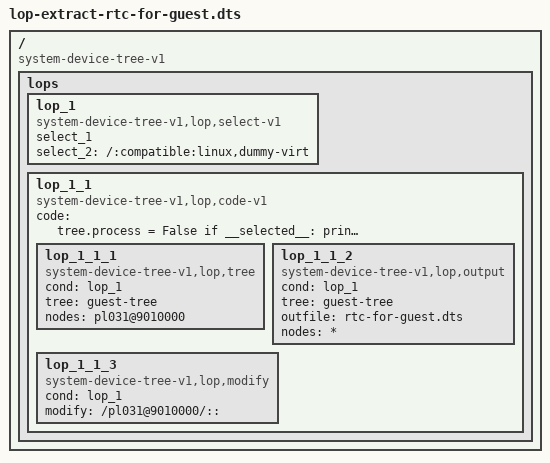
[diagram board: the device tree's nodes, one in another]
/dts-v1/;

/ {
	compatible = "system-device-tree-v1";
	lops {
		// Select the QEMU virt device tree (compatible = "linux,dummy-virt")
		lop_1: lop_1 {
			compatible = "system-device-tree-v1,lop,select-v1";
			// clear any old selections
			select_1;
			select_2 = "/:compatible:linux,dummy-virt";
		};

		lop_1_1: lop_1_1 {
			compatible = "system-device-tree-v1,lop,code-v1";
			code = "
				tree.process = False
				if __selected__:
					print('Compatible dts (qemu virt) found: %s' % node)
					tree.process = True

				if __selected__:
					return True
				else:
					return False
				";

			// Build a virtual tree containing only the RTC node
			lop_1_1_1 {
				compatible = "system-device-tree-v1,lop,tree";
				cond = <&lop_1>;
				tree = "guest-tree";
				nodes = "pl031@9010000";
			};

			// Output the guest tree to rtc-for-guest.dts
			lop_1_1_2 {
				compatible = "system-device-tree-v1,lop,output";
				cond = <&lop_1>;
				tree = "guest-tree";
				outfile = "rtc-for-guest.dts";
				nodes = "*";
			};

			// Delete the RTC node from the Linux device tree
			lop_1_1_3 {
				compatible = "system-device-tree-v1,lop,modify";
				cond = <&lop_1>;
				modify = "/pl031@9010000/::";
			};
		};
	};
};
